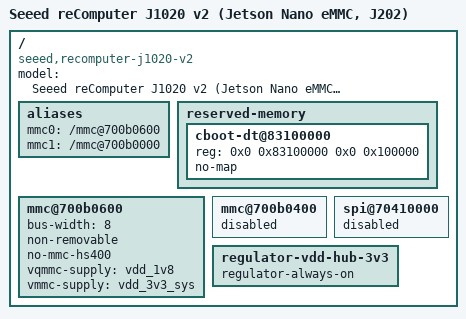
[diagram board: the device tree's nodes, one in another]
// SPDX-License-Identifier: GPL-2.0
/*
 * Seeed reComputer J1020 v2: Jetson Nano 4 GB production module (P3448-0002,
 * 16 GB eMMC) on the Seeed J202 carrier board.
 *
 * Seeed flashes this board with NVIDIA's stock `jetson-nano-emmc` config, so
 * the board is electrically the NVIDIA eMMC module on a devkit-like carrier.
 * Mainline's tegra210-p3450-0000.dts describes the SD-card module (P3448-0000)
 * instead. The differences that matter, applied on top of it:
 *
 *  1. SDMMC4 (mmc@700b0600): the module's 8-bit eMMC. Absent from p3450, so
 *     without it the kernel never sees the eMMC. Same shape as the TX1 module
 *     (tegra210-p2180.dtsi), which also has its eMMC on SDMMC4.
 *  2. SDMMC1 (mmc@700b0000): on P3448-0000 this is the module's own microSD
 *     socket; on P3448-0002 the same pins go to the J202's microSD slot.
 *     Kept enabled with p3450's card-detect GPIO. UNVERIFIED: compare
 *     cd-gpios with the Seeed DTB (hardware/inventory-j202.sh dumps it).
 *  3. SDMMC3 (mmc@700b0400): SDIO for the devkit's M.2 Key E. Seeed says the
 *     J202's Key E slot only works with Xavier NX modules, so it is disabled.
 *
 * Unchanged and expected to work as on p3450: PCIe (pci@2,0 is the module's
 * own RTL8111 Ethernet; pci@1,0 reaches the J202's M.2 Key M at x1), HDMI
 * (sor1), DP (sor0 + dpaux), XUSB, PMIC, thermal.
 *
 *  4. QSPI (spi@70410000): no NOR flash on the eMMC module; disabled.
 *
 *  5. VDD_HUB_3V3 (GPIO PA6, the module's MOD_SLEEP* pin) stays on: on the
 *     J202 it also gates the HDMI connector's supply.
 *
 * Status: linux-nano 7.2.11 boots it from the NVMe root (2026-11-24): PWM fan,
 * GPU regulator and nouveau up, EMC at 1600 MHz with cboot's trained tables
 * (make-j202-nano-dtb.sh). HDMI works with 5.
 */

#include "tegra210-p3450-0000.dts"

/ {
	model = "Seeed reComputer J1020 v2 (Jetson Nano eMMC, J202)";
	compatible = "seeed,recomputer-j1020-v2",
		     "nvidia,p3449-0000-b00+p3448-0002-b00",
		     "nvidia,jetson-nano", "nvidia,tegra210";

	aliases {
		mmc0 = "/mmc@700b0600";
		mmc1 = "/mmc@700b0000";
	};

	/*
	 * cboot trains the DRAM on every boot and leaves its own kernel device
	 * tree, with the trained EMC tables, in RAM at 0x83100000. L4T U-Boot
	 * loads ours at 0x83000000 and the initrd at 0x83200000, so that blob
	 * survives until the kernel starts. Keep it (no-map: readable through
	 * /dev/mem with STRICT_DEVMEM) so its EMC tables can be used.
	 */
	reserved-memory {
		cboot-dt@83100000 {
			reg = <0x0 0x83100000 0x0 0x100000>;
			no-map;
		};
	};

	/* eMMC on the module */
	mmc@700b0600 {
		status = "okay";
		bus-width = <8>;
		non-removable;
		/* HS400 fails now and then (recovery error -110, no /boot): HS200 is enough */
		no-mmc-hs400;
		vqmmc-supply = <&vdd_1v8>;
		vmmc-supply = <&vdd_3v3_sys>;
	};

	/* Key E SDIO: not routed for a Nano module on the J202 */
	mmc@700b0400 {
		status = "disabled";
	};

	/*
	 * QSPI NOR: the SD-card module boots from it, the eMMC module has none.
	 * Left enabled, spi-tegra210-quad times out and spi-nor fails with -5
	 * (seen on the first boot, 2026-11-23).
	 */
	spi@70410000 {
		status = "disabled";
	};

	/*
	 * MOD_SLEEP* (PA6) switches VDD_3V3_HDMI on the J202 (schematic sheet
	 * 13): HDMI 5 V, the DDC level shifter and hot-plug detect. Nothing
	 * uses this regulator, so the kernel would turn it off at boot and the
	 * monitor would never be detected.
	 */
	regulator-vdd-hub-3v3 {
		regulator-always-on;
	};
};
